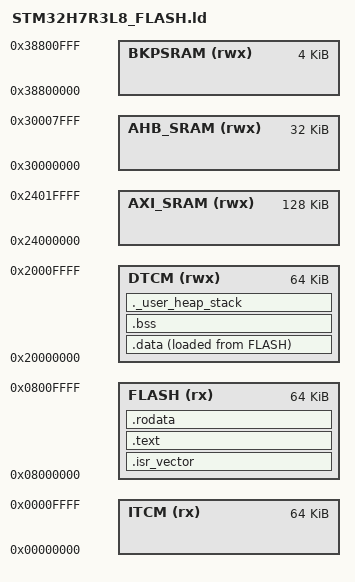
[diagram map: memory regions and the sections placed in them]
/* Linker script for STM32H7R3L8HxH - 64KB Flash, 64KB DTCM */
MEMORY
{
  ITCM   (rx)  : ORIGIN = 0x00000000, LENGTH = 64K
  FLASH  (rx)  : ORIGIN = 0x08000000, LENGTH = 64K
  DTCM   (rwx) : ORIGIN = 0x20000000, LENGTH = 64K
  AXI_SRAM (rwx) : ORIGIN = 0x24000000, LENGTH = 128K
  AHB_SRAM (rwx) : ORIGIN = 0x30000000, LENGTH = 32K
  BKPSRAM (rwx) : ORIGIN = 0x38800000, LENGTH = 4K
}

ENTRY(Reset_Handler)

_estack = ORIGIN(DTCM) + LENGTH(DTCM);

SECTIONS
{
  .isr_vector :
  {
    . = ALIGN(4);
    KEEP(*(.isr_vector))
    . = ALIGN(4);
  } >FLASH

  .text :
  {
    . = ALIGN(4);
    *(.text)
    *(.text*)
    *(.glue_7)
    *(.glue_7t)
    *(.eh_frame)
    KEEP(*(.init))
    KEEP(*(.fini))
    . = ALIGN(4);
    _etext = .;
  } >FLASH

  .rodata :
  {
    . = ALIGN(4);
    *(.rodata)
    *(.rodata*)
    . = ALIGN(4);
  } >FLASH

  _sidata = LOADADDR(.data);

  .data :
  {
    . = ALIGN(4);
    _sdata = .;
    *(.data)
    *(.data*)
    . = ALIGN(4);
    _edata = .;
  } >DTCM AT> FLASH

  .bss :
  {
    . = ALIGN(4);
    _sbss = .;
    __bss_start__ = _sbss;
    *(.bss)
    *(.bss*)
    *(COMMON)
    . = ALIGN(4);
    _ebss = .;
    __bss_end__ = _ebss;
  } >DTCM

  ._user_heap_stack :
  {
    . = ALIGN(8);
    PROVIDE(end = .);
    PROVIDE(_end = .);
    . = . + 0x400;
    . = ALIGN(8);
  } >DTCM
}
